# STM32H743 register map
File version: 2.4
CPU: CM7 r0p1, little endian, MPU, FPU, 4 interrupt priority bits
Registers are 32-bit, read-write, reset 0x0 unless marked. A register's access mark holds for its fields unless they carry their own. Offsets are from the block's base; [hi:lo] are bit positions; {n}, {i} and the like mark numbered series.

## Ethernet_MAC — 以太网：介质访问控制（MAC）
Base 0x40028000
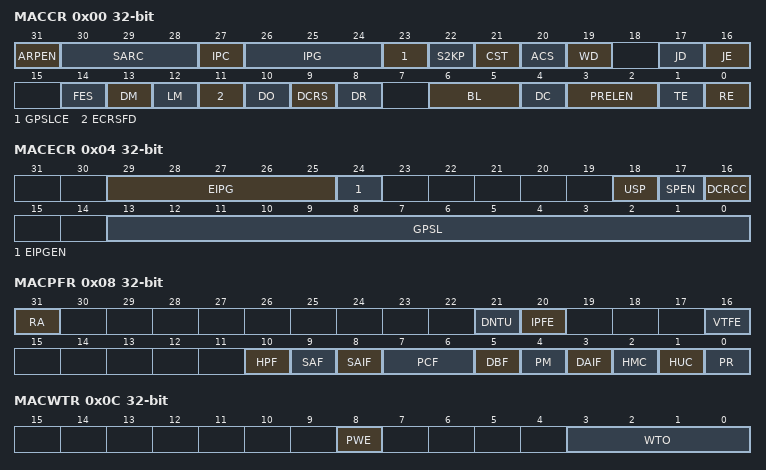
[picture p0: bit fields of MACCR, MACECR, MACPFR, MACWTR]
0x00 MACCR — 工作模式配置寄存器
  [31] ARPEN
  [30:28] SARC
  [27] IPC
  [26:24] IPG
  [23] GPSLCE
  [22] S2KP
  [21] CST
  [20] ACS
  [19] WD
  [17] JD
  [16] JE
  [14] FES
  [13] DM
  [12] LM
  [11] ECRSFD
  [10] DO
  [9] DCRS
  [8] DR
  [6:5] BL
  [4] DC
  [3:2] PRELEN
  [1] TE
  [0] RE — 接收器使能
0x04 MACECR — 扩展工作模式配置寄存器
  [29:25] EIPG, [24] EIPGEN, [18] USP, [17] SPEN, [16] DCRCC, [13:0] GPSL
0x08 MACPFR — 数据包过滤控制寄存器
  [31] RA, [21] DNTU, [20] IPFE, [16] VTFE, [10] HPF, [9] SAF, [8] SAIF, [7:6] PCF, [5] DBF, [4] PM, [3] DAIF, [2] HMC, [1] HUC, [0] PR
0x0C MACWTR — 看门狗超时寄存器
  [8] PWE, [3:0] WTO
0x10 MACHT0R — 哈希表 0 寄存器
  [31:0] HT31T0
0x14 MACHT1R — 哈希表 1 寄存器
  [31:0] HT63T32
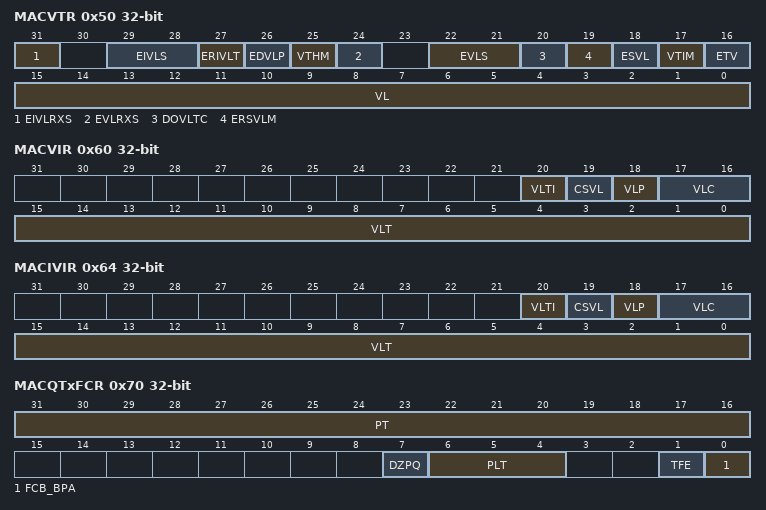
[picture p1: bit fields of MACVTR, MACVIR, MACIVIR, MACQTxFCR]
0x50 MACVTR — VLAN 标签寄存器
  [31] EIVLRXS, [29:28] EIVLS, [27] ERIVLT, [26] EDVLP, [25] VTHM, [24] EVLRXS, [22:21] EVLS, [20] DOVLTC, [19] ERSVLM, [18] ESVL, [17] VTIM, [16] ETV, [15:0] VL
0x58 MACVHTR — VLAN 哈希表寄存器
  [15:0] VLHT
0x60 MACVIR — VLAN 包含寄存器
  [20] VLTI, [19] CSVL, [18] VLP, [17:16] VLC, [15:0] VLT
0x64 MACIVIR — 内部 VLAN 包含寄存器
  [20] VLTI, [19] CSVL, [18] VLP, [17:16] VLC, [15:0] VLT
0x70 MACQTxFCR — 发送队列流控寄存器
  [31:16] PT, [7] DZPQ, [6:4] PLT, [1] TFE, [0] FCB_BPA
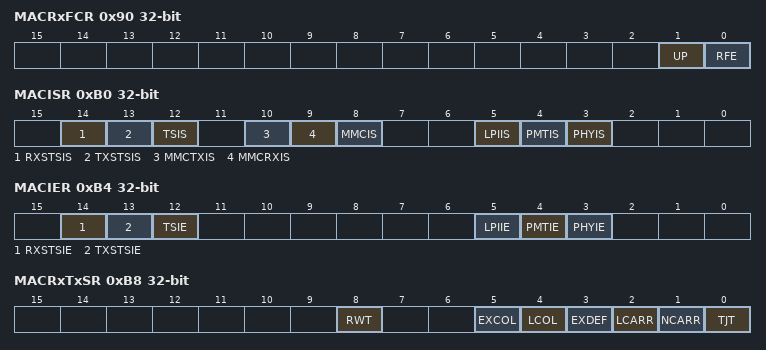
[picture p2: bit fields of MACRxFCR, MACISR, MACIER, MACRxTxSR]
0x90 MACRxFCR — 接收流控寄存器
  [1] UP, [0] RFE
0xB0 MACISR ro — 中断状态寄存器
  [14] RXSTSIS, [13] TXSTSIS, [12] TSIS, [10] MMCTXIS, [9] MMCRXIS, [8] MMCIS, [5] LPIIS, [4] PMTIS, [3] PHYIS
0xB4 MACIER — 中断使能寄存器
  [14] RXSTSIE, [13] TXSTSIE, [12] TSIE, [5] LPIIE, [4] PMTIE, [3] PHYIE
0xB8 MACRxTxSR ro — 收发状态寄存器
  [8] RWT
  [5] EXCOL — LCOL
  [4] LCOL
  [3] EXDEF
  [2] LCARR
  [1] NCARR
  [0] TJT
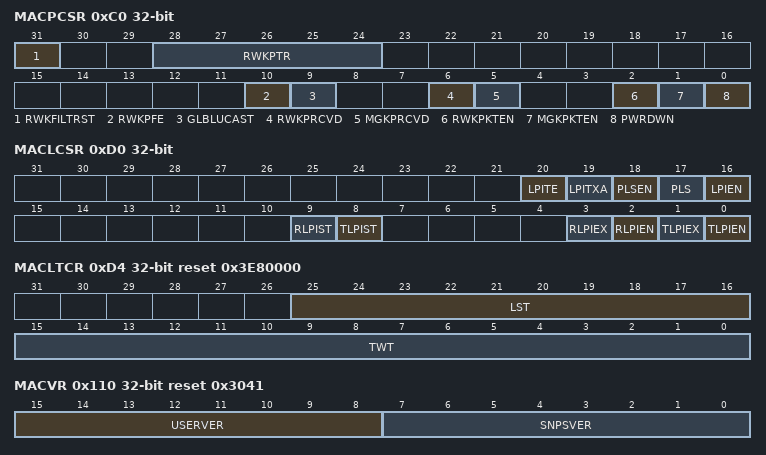
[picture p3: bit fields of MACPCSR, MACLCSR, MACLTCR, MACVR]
0xC0 MACPCSR access per field — PMT 控制状态寄存器
  [31] RWKFILTRST rw, [28:24] RWKPTR rw, [10] RWKPFE rw, [9] GLBLUCAST rw, [6] RWKPRCVD ro, [5] MGKPRCVD ro, [2] RWKPKTEN rw, [1] MGKPKTEN rw, [0] PWRDWN rw
0xC4 MACRWKPFR — 唤醒数据包过滤清除寄存器
0xD0 MACLCSR access per field — LPI 控制状态寄存器
  [20] LPITE rw, [19] LPITXA rw, [18] PLSEN rw, [17] PLS rw, [16] LPIEN rw, [9] RLPIST ro, [8] TLPIST ro, [3] RLPIEX ro, [2] RLPIEN ro, [1] TLPIEX ro, [0] TLPIEN ro
0xD4 MACLTCR reset 0x3E80000 — LPI 定时器控制寄存器
  [25:16] LST, [15:0] TWT
0xD8 MACLETR — LPI 进入定时器寄存器
  [16:0] LPIET
0xDC MAC1USTCR — 1 微秒滴答计数器寄存器
  [11:0] TIC_1US_CNTR
0x110 MACVR ro reset 0x3041 — 版本寄存器
  [15:8] USERVER, [7:0] SNPSVER
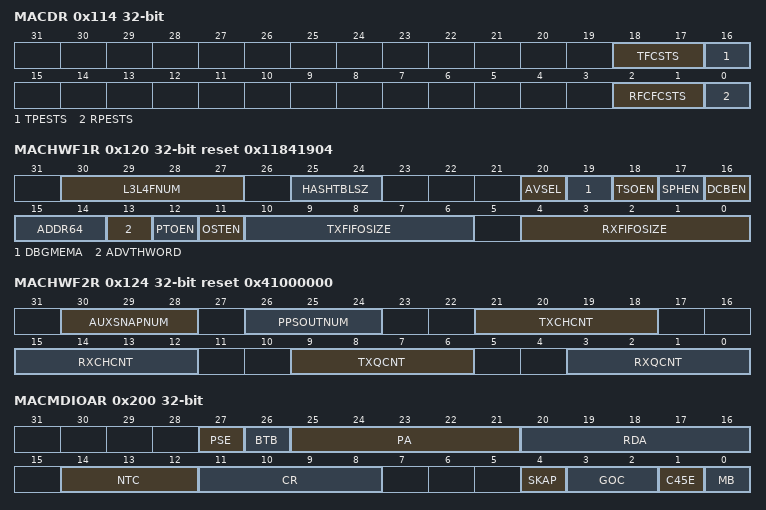
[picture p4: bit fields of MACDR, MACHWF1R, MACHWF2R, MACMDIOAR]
0x114 MACDR ro — 调试寄存器
  [18:17] TFCSTS, [16] TPESTS, [2:1] RFCFCSTS, [0] RPESTS
0x120 MACHWF1R ro reset 0x11841904 — 硬件特性 1 寄存器
  [30:27] L3L4FNUM, [25:24] HASHTBLSZ, [20] AVSEL, [19] DBGMEMA, [18] TSOEN, [17] SPHEN, [16] DCBEN, [15:14] ADDR64, [13] ADVTHWORD, [12] PTOEN, [11] OSTEN, [10:6] TXFIFOSIZE, [4:0] RXFIFOSIZE
0x124 MACHWF2R ro reset 0x41000000 — 硬件特性 2 寄存器
  [30:28] AUXSNAPNUM, [26:24] PPSOUTNUM, [21:18] TXCHCNT, [15:12] RXCHCNT, [9:6] TXQCNT, [3:0] RXQCNT
0x200 MACMDIOAR — MDIO 地址寄存器
  [27] PSE, [26] BTB, [25:21] PA, [20:16] RDA, [14:12] NTC, [11:8] CR, [4] SKAP, [3:2] GOC, [1] C45E, [0] MB
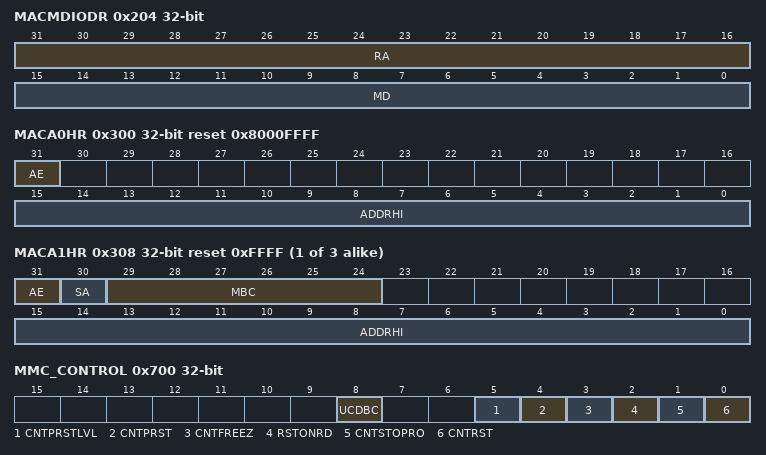
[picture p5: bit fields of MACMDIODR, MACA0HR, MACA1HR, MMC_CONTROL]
0x204 MACMDIODR — MDIO 数据寄存器
  [31:16] RA, [15:0] MD
0x300 MACA0HR access per field reset 0x8000FFFF — 地址 0 高位寄存器
  [31] AE ro, [15:0] ADDRHI rw
{0x304+8i} MACA{i}LR reset 0xFFFFFFFF (i=0..3) — 地址 {i} 低位寄存器
  [31:0] ADDRLO
{0x300+8i} MACA{i}HR reset 0xFFFF (i=1..3) — 地址 {i} 高位寄存器
  [31] AE, [30] SA, [29:24] MBC, [15:0] ADDRHI
0x700 MMC_CONTROL — MMC 控制寄存器
  [8] UCDBC, [5] CNTPRSTLVL, [4] CNTPRST, [3] CNTFREEZ, [2] RSTONRD, [1] CNTSTOPRO, [0] CNTRST
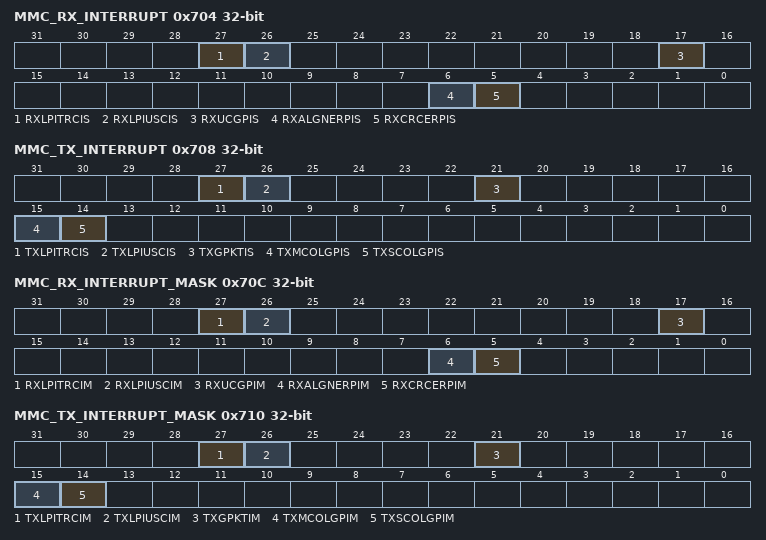
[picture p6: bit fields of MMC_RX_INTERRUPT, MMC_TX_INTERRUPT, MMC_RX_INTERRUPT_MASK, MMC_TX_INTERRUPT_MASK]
0x704 MMC_RX_INTERRUPT ro — MMC 接收中断寄存器
  [27] RXLPITRCIS, [26] RXLPIUSCIS, [17] RXUCGPIS, [6] RXALGNERPIS, [5] RXCRCERPIS
0x708 MMC_TX_INTERRUPT ro — MMC 发送中断寄存器
  [27] TXLPITRCIS, [26] TXLPIUSCIS, [21] TXGPKTIS, [15] TXMCOLGPIS, [14] TXSCOLGPIS
0x70C MMC_RX_INTERRUPT_MASK access per field — MMC 接收中断屏蔽寄存器
  [27] RXLPITRCIM ro, [26] RXLPIUSCIM rw, [17] RXUCGPIM rw, [6] RXALGNERPIM rw, [5] RXCRCERPIM rw
0x710 MMC_TX_INTERRUPT_MASK access per field — MMC 发送中断屏蔽寄存器
  [27] TXLPITRCIM ro, [26] TXLPIUSCIM rw, [21] TXGPKTIM rw, [15] TXMCOLGPIM rw, [14] TXSCOLGPIM rw
0x74C TX_SINGLE_COLLISION_GOOD_PACKETS ro — 发送单次冲突正常数据包寄存器
  [31:0] TXSNGLCOLG
0x750 TX_MULTIPLE_COLLISION_GOOD_PACKETS ro — 发送多次冲突正常数据包寄存器
  [31:0] TXMULTCOLG
0x768 TX_PACKET_COUNT_GOOD ro — 发送正常数据包计数寄存器
  [31:0] TXPKTG
0x794 RX_CRC_ERROR_PACKETS ro — 接收 CRC 错误数据包寄存器
  [31:0] RXCRCERR
0x798 RX_ALIGNMENT_ERROR_PACKETS ro — 接收对齐错误数据包寄存器
  [31:0] RXALGNERR
0x7C4 RX_UNICAST_PACKETS_GOOD ro — 接收正常单播数据包寄存器
  [31:0] RXUCASTG
0x7EC TX_LPI_USEC_CNTR ro — 发送 LPI 微秒定时器寄存器
  [31:0] TXLPIUSC
0x7F0 TX_LPI_TRAN_CNTR ro — 发送 LPI 转换计数器寄存器
  [31:0] TXLPITRC
0x7F4 RX_LPI_USEC_CNTR ro — 接收 LPI 微秒计数器寄存器
  [31:0] RXLPIUSC
0x7F8 RX_LPI_TRAN_CNTR ro — 接收 LPI 转换计数器寄存器
  [31:0] RXLPITRC
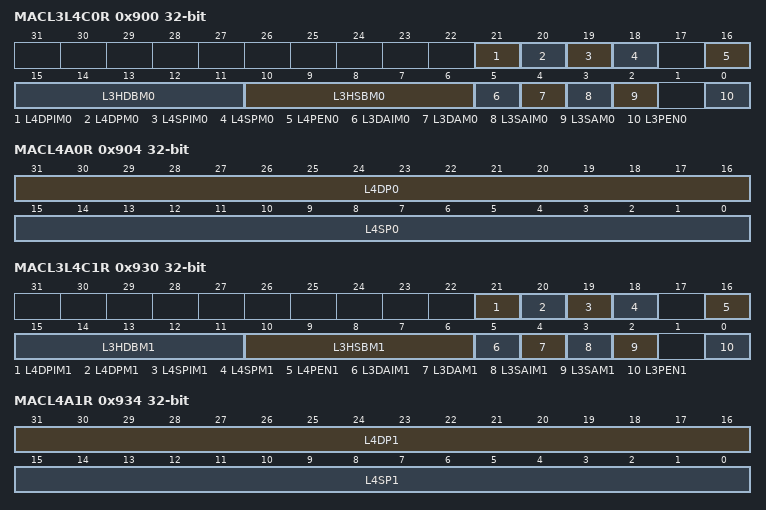
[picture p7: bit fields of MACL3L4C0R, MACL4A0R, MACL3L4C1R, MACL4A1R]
0x900 MACL3L4C0R — L3/L4 控制 0 寄存器
  [21] L4DPIM0, [20] L4DPM0, [19] L4SPIM0, [18] L4SPM0, [16] L4PEN0, [15:11] L3HDBM0, [10:6] L3HSBM0, [5] L3DAIM0, [4] L3DAM0, [3] L3SAIM0, [2] L3SAM0, [0] L3PEN0
0x904 MACL4A0R — 第 4 层地址过滤 0 寄存器
  [31:16] L4DP0, [15:0] L4SP0
0x910 MACL3A00R — 第 3 层地址 0 过滤 0 寄存器
  [31:0] L3A00
0x914 MACL3A10R — 第 3 层地址 1 过滤 0 寄存器
  [31:0] L3A10
0x918 MACL3A20 — 第 3 层地址 2 过滤 0 寄存器
  [31:0] L3A20
0x91C MACL3A30 — 第 3 层地址 3 过滤 0 寄存器
  [31:0] L3A30
0x930 MACL3L4C1R — L3/L4 控制 1 寄存器
  [21] L4DPIM1, [20] L4DPM1, [19] L4SPIM1, [18] L4SPM1, [16] L4PEN1, [15:11] L3HDBM1, [10:6] L3HSBM1, [5] L3DAIM1, [4] L3DAM1, [3] L3SAIM1, [2] L3SAM1, [0] L3PEN1
0x934 MACL4A1R — 第 4 层地址过滤 1 寄存器
  [31:16] L4DP1, [15:0] L4SP1
0x940 MACL3A01R — 第 3 层地址 0 过滤 1 寄存器
  [31:0] L3A01
0x944 MACL3A11R — 第 3 层地址 1 过滤 1 寄存器
  [31:0] L3A11
0x948 MACL3A21R — 第 3 层地址 2 过滤 1 寄存器
  [31:0] L3A21
0x94C MACL3A31R — 第 3 层地址 3 过滤 1 寄存器
  [31:0] L3A31
0xAE0 MACARPAR — ARP 地址寄存器
  [31:0] ARPPA
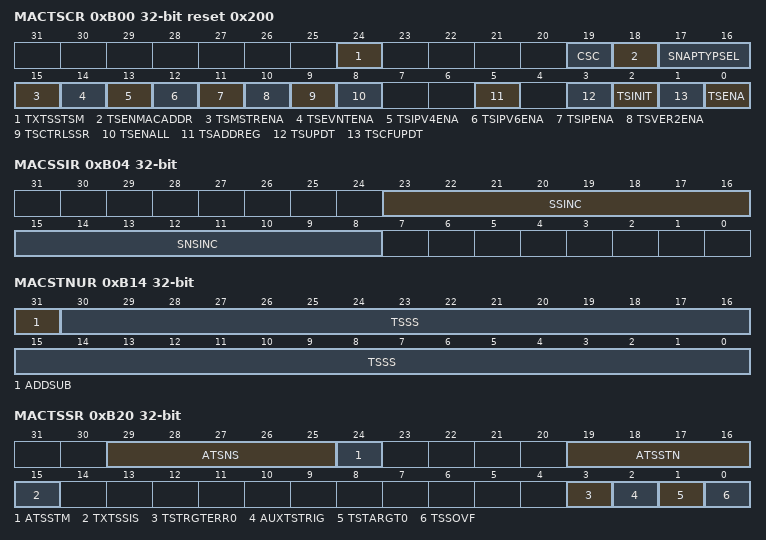
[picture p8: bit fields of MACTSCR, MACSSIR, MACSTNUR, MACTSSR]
0xB00 MACTSCR access per field reset 0x200 — 时间戳控制寄存器
  [24] TXTSSTSM rw, [19] CSC ro, [18] TSENMACADDR rw, [17:16] SNAPTYPSEL rw, [15] TSMSTRENA rw, [14] TSEVNTENA rw, [13] TSIPV4ENA rw, [12] TSIPV6ENA rw, [11] TSIPENA rw, [10] TSVER2ENA rw, [9] TSCTRLSSR rw, [8] TSENALL rw, [5] TSADDREG rw, [3] TSUPDT rw, [2] TSINIT rw, [1] TSCFUPDT rw, [0] TSENA rw
0xB04 MACSSIR — 亚秒增量寄存器
  [23:16] SSINC, [15:8] SNSINC
0xB08 MACSTSR ro — 系统时间（秒）寄存器
  [31:0] TSS
0xB0C MACSTNR ro — 系统时间（纳秒）寄存器
  [30:0] TSSS
0xB10 MACSTSUR — 系统时间秒更新寄存器
  [31:0] TSS
0xB14 MACSTNUR — 系统时间纳秒更新寄存器
  [31] ADDSUB, [30:0] TSSS
0xB18 MACTSAR — 时间戳加数寄存器
  [31:0] TSAR
0xB20 MACTSSR ro — 时间戳状态寄存器
  [29:25] ATSNS, [24] ATSSTM, [19:16] ATSSTN, [15] TXTSSIS, [3] TSTRGTERR0, [2] AUXTSTRIG, [1] TSTARGT0, [0] TSSOVF
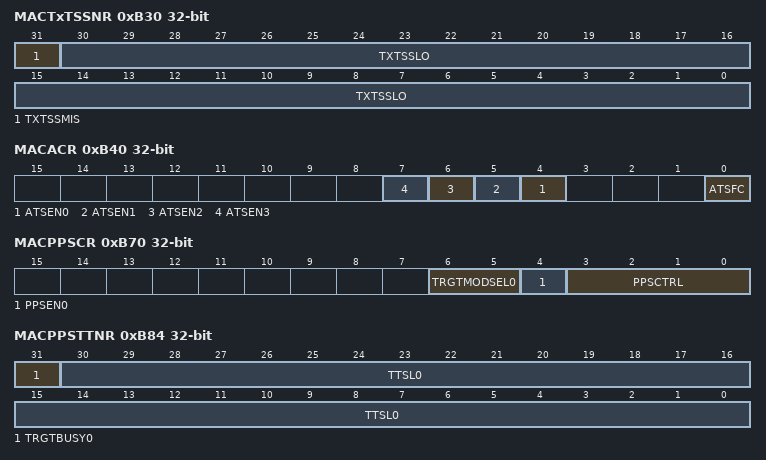
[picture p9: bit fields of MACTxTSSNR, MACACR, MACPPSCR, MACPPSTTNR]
0xB30 MACTxTSSNR ro — 发送时间戳状态纳秒寄存器
  [31] TXTSSMIS, [30:0] TXTSSLO
0xB34 MACTxTSSSR ro — 发送时间戳状态秒寄存器
  [31:0] TXTSSHI
0xB40 MACACR — 辅助控制寄存器
  [n+4] ATSEN{n} (n=0..3), [0] ATSFC
0xB48 MACATSNR ro — 辅助时间戳纳秒寄存器
  [30:0] AUXTSLO
0xB4C MACATSSR ro — 辅助时间戳秒寄存器
  [31:0] AUXTSHI
0xB50 MACTSIACR — 时间戳入口非对称校正寄存器
  [31:0] OSTIAC
0xB54 MACTSEACR — 时间戳出口非对称校正寄存器
  [31:0] OSTEAC
0xB58 MACTSICNR — 时间戳入口校正纳秒寄存器
  [31:0] TSIC
0xB5C MACTSECNR — 时间戳出口校正纳秒寄存器
  [31:0] TSEC
0xB70 MACPPSCR — PPS 控制寄存器
  [6:5] TRGTMODSEL0, [4] PPSEN0, [3:0] PPSCTRL
0xB80 MACPPSTTSR — PPS 目标时间秒寄存器
  [30:0] TSTRH0
0xB84 MACPPSTTNR — PPS 目标时间纳秒寄存器
  [31] TRGTBUSY0, [30:0] TTSL0
0xB88 MACPPSIR — PPS 间隔寄存器
  [31:0] PPSINT0
0xB8C MACPPSWR — PPS 宽度寄存器
  [31:0] PPSWIDTH0
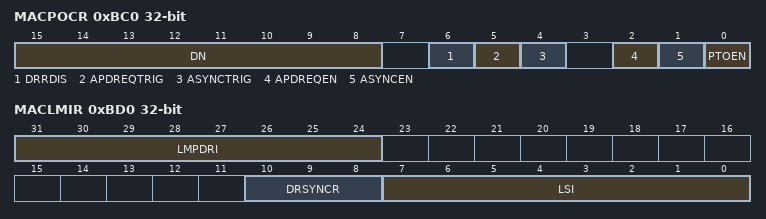
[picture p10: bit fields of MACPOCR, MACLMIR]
0xBC0 MACPOCR — PTP 卸载控制寄存器
  [15:8] DN, [6] DRRDIS, [5] APDREQTRIG, [4] ASYNCTRIG, [2] APDREQEN, [1] ASYNCEN, [0] PTOEN
0xBC4 MACSPI0R — PTP 源端口标识 0 寄存器
  [31:0] SPI0
0xBC8 MACSPI1R — PTP 源端口标识 1 寄存器
  [31:0] SPI1
0xBCC MACSPI2R — PTP 源端口标识 2 寄存器
  [15:0] SPI2
0xBD0 MACLMIR — 日志消息间隔寄存器
  [31:24] LMPDRI, [10:8] DRSYNCR, [7:0] LSI
